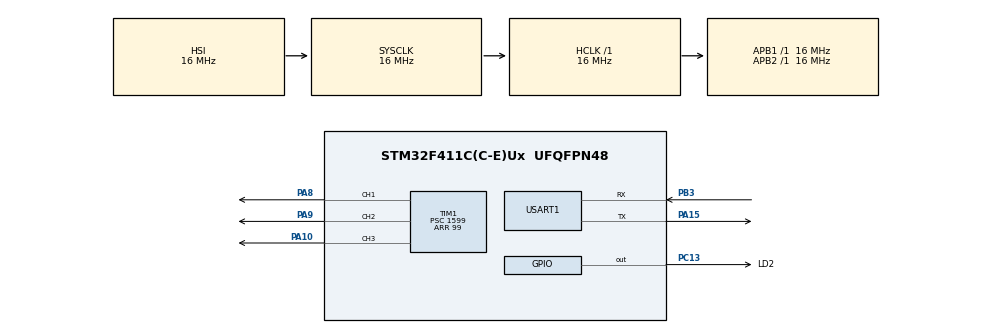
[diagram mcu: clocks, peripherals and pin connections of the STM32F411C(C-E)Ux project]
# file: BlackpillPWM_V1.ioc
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Mcu.Family=STM32F4
Mcu.Name=STM32F411C(C-E)Ux
Mcu.Package=UFQFPN48
NVIC.PriorityGroup=NVIC_PRIORITYGROUP_4
PA10.Signal=S_TIM1_CH3
PA13.Mode=Serial_Wire
PA13.Signal=SYS_JTMS-SWDIO
PA14.Mode=Serial_Wire
PA14.Signal=SYS_JTCK-SWCLK
PA15.Mode=Asynchronous
PA15.Signal=USART1_TX
PA8.Signal=S_TIM1_CH1
PA9.Signal=S_TIM1_CH2
PB3.Mode=Asynchronous
PB3.Signal=USART1_RX
PC13-ANTI_TAMP.GPIO_Label=LD2
PC13-ANTI_TAMP.Signal=GPIO_Output
PC14-OSC32_IN.Mode=LSE-External-Oscillator
PC14-OSC32_IN.Signal=RCC_OSC32_IN
PC15-OSC32_OUT.Mode=LSE-External-Oscillator
PC15-OSC32_OUT.Signal=RCC_OSC32_OUT
PH0\ -\ OSC_IN.Mode=HSE-External-Oscillator
PH0\ -\ OSC_IN.Signal=RCC_OSC_IN
PH1\ -\ OSC_OUT.Mode=HSE-External-Oscillator
PH1\ -\ OSC_OUT.Signal=RCC_OSC_OUT
ProjectManager.HeapSize=0x200
ProjectManager.StackSize=0x400
ProjectManager.TargetToolchain=STM32CubeIDE
RCC.AHBFreq_Value=16000000
RCC.APB1Freq_Value=16000000
RCC.APB2Freq_Value=16000000
RCC.CortexFreq_Value=16000000
RCC.HSE_VALUE=25000000
RCC.HSI_VALUE=16000000
RCC.SYSCLKFreq_VALUE=16000000
RCC.VCOOutputFreq_Value=192000000
SH.S_TIM1_CH1.0=TIM1_CH1,PWM Generation1 CH1
SH.S_TIM1_CH2.0=TIM1_CH2,PWM Generation2 CH2
SH.S_TIM1_CH3.0=TIM1_CH3,PWM Generation3 CH3
TIM1.Channel-PWM\ Generation1\ CH1=TIM_CHANNEL_1
TIM1.Channel-PWM\ Generation2\ CH2=TIM_CHANNEL_2
TIM1.Channel-PWM\ Generation3\ CH3=TIM_CHANNEL_3
TIM1.Period=99
TIM1.Prescaler=1599
TIM1.Pulse-PWM\ Generation1\ CH1=50
TIM1.Pulse-PWM\ Generation2\ CH2=70
TIM1.Pulse-PWM\ Generation3\ CH3=160
USART1.VirtualMode=VM_ASYNC
board=custom

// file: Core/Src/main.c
/* USER CODE BEGIN Header */
/**
  ******************************************************************************
  * @file           : main.c
  * @brief          : Main program body
  ******************************************************************************
  * @attention
  *
  * Copyright (c) 2025 STMicroelectronics.
  * All rights reserved.
  *
  * This software is licensed under terms that can be found in the LICENSE file
  * in the root directory of this software component.
  * If no LICENSE file comes with this software, it is provided AS-IS.
  *
  ******************************************************************************
  */
/* USER CODE END Header */
#include "main.h"
#include "tim.h"
#include "usart.h"
#include "gpio.h"

void SystemClock_Config(void);

int main(void)
{

  /* MCU Configuration--------------------------------------------------------*/

  /* Reset of all peripherals, Initializes the Flash interface and the Systick. */
  HAL_Init();

  /* Configure the system clock */
  SystemClock_Config();

  /* Initialize all configured peripherals */
  MX_GPIO_Init();
  MX_USART1_UART_Init();
  MX_TIM1_Init();
  /* USER CODE BEGIN 2 */
  HAL_TIM_PWM_Start(&htim1, TIM_CHANNEL_1);
  HAL_TIM_PWM_Start(&htim1, TIM_CHANNEL_2);

  HAL_TIM_PWM_Start(&htim1, TIM_CHANNEL_3);

  /* USER CODE END 2 */

  /* Infinite loop */
  /* USER CODE BEGIN WHILE */
  while (1)
  {

	  //HAL_GPIO_TogglePin(LD2_GPIO_Port, LD2_Pin);
	  //HAL_Delay(500);
    /* USER CODE END WHILE */

  }
}

void SystemClock_Config(void)
{
  RCC_OscInitTypeDef RCC_OscInitStruct = {0};
  RCC_ClkInitTypeDef RCC_ClkInitStruct = {0};

  /** Configure the main internal regulator output voltage
  */
  __HAL_RCC_PWR_CLK_ENABLE();
  __HAL_PWR_VOLTAGESCALING_CONFIG(PWR_REGULATOR_VOLTAGE_SCALE1);

  /** Initializes the RCC Oscillators according to the specified parameters
  * in the RCC_OscInitTypeDef structure.
  */
  RCC_OscInitStruct.OscillatorType = RCC_OSCILLATORTYPE_HSI;
  RCC_OscInitStruct.HSIState = RCC_HSI_ON;
  RCC_OscInitStruct.HSICalibrationValue = RCC_HSICALIBRATION_DEFAULT;
  RCC_OscInitStruct.PLL.PLLState = RCC_PLL_NONE;
  if (HAL_RCC_OscConfig(&RCC_OscInitStruct) != HAL_OK)
  {
    Error_Handler();
  }

  /** Initializes the CPU, AHB and APB buses clocks
  */
  RCC_ClkInitStruct.ClockType = RCC_CLOCKTYPE_HCLK|RCC_CLOCKTYPE_SYSCLK
                              |RCC_CLOCKTYPE_PCLK1|RCC_CLOCKTYPE_PCLK2;
  RCC_ClkInitStruct.SYSCLKSource = RCC_SYSCLKSOURCE_HSI;
  RCC_ClkInitStruct.AHBCLKDivider = RCC_SYSCLK_DIV1;
  RCC_ClkInitStruct.APB1CLKDivider = RCC_HCLK_DIV1;
  RCC_ClkInitStruct.APB2CLKDivider = RCC_HCLK_DIV1;

  if (HAL_RCC_ClockConfig(&RCC_ClkInitStruct, FLASH_LATENCY_0) != HAL_OK)
  {
    Error_Handler();
  }
}

void Error_Handler(void)
{
  __disable_irq();
  while (1)
  {
  }
}
